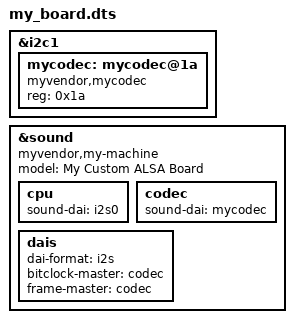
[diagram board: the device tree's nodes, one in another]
&i2c1 {
    mycodec: mycodec@1a {
        compatible = "myvendor,mycodec";
        reg = <0x1a>;
        #sound-dai-cells = <0>;
    };
};

/* Node "sound" để tạo platform device cho machine driver */
&sound {
    compatible = "myvendor,my-machine";
    model = "My Custom ALSA Board";

    cpu {
        sound-dai = <&i2s0>;        /* CPU DAI phandle */
    };

    codec {
        sound-dai = <&mycodec>;     /* CODEC DAI phandle */
    };

    dais {
        dai-format = "i2s";
        bitclock-master = <&codec>; /* codec master bitclock */
        frame-master    = <&codec>; /* codec master lrclk   */
    };
};
